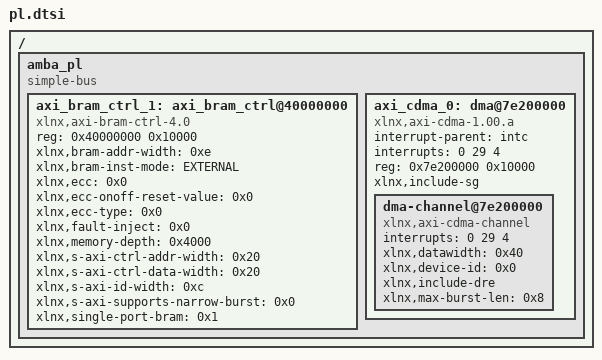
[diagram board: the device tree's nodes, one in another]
/*
 * CAUTION: This file is automatically generated by Xilinx.
 * Version:  
 * Today is: Tue Mar 14 18:04:00 2017
*/


/ {
	amba_pl: amba_pl {
		#address-cells = <1>;
		#size-cells = <1>;
		compatible = "simple-bus";
		ranges ;
		axi_bram_ctrl_1: axi_bram_ctrl@40000000 {
			compatible = "xlnx,axi-bram-ctrl-4.0";
			reg = <0x40000000 0x10000>;
			xlnx,bram-addr-width = <0xe>;
			xlnx,bram-inst-mode = "EXTERNAL";
			xlnx,ecc = <0x0>;
			xlnx,ecc-onoff-reset-value = <0x0>;
			xlnx,ecc-type = <0x0>;
			xlnx,fault-inject = <0x0>;
			xlnx,memory-depth = <0x4000>;
			xlnx,s-axi-ctrl-addr-width = <0x20>;
			xlnx,s-axi-ctrl-data-width = <0x20>;
			xlnx,s-axi-id-width = <0xc>;
			xlnx,s-axi-supports-narrow-burst = <0x0>;
			xlnx,single-port-bram = <0x1>;
		};
		axi_cdma_0: dma@7e200000 {
			#dma-cells = <1>;
			compatible = "xlnx,axi-cdma-1.00.a";
			interrupt-parent = <&intc>;
			interrupts = <0 29 4>;
			reg = <0x7e200000 0x10000>;
			xlnx,include-sg ;
			dma-channel@7e200000 {
				compatible = "xlnx,axi-cdma-channel";
				interrupts = <0 29 4>;
				xlnx,datawidth = <0x40>;
				xlnx,device-id = <0x0>;
				xlnx,include-dre ;
				xlnx,max-burst-len = <0x8>;
			};
		};
	};
};
